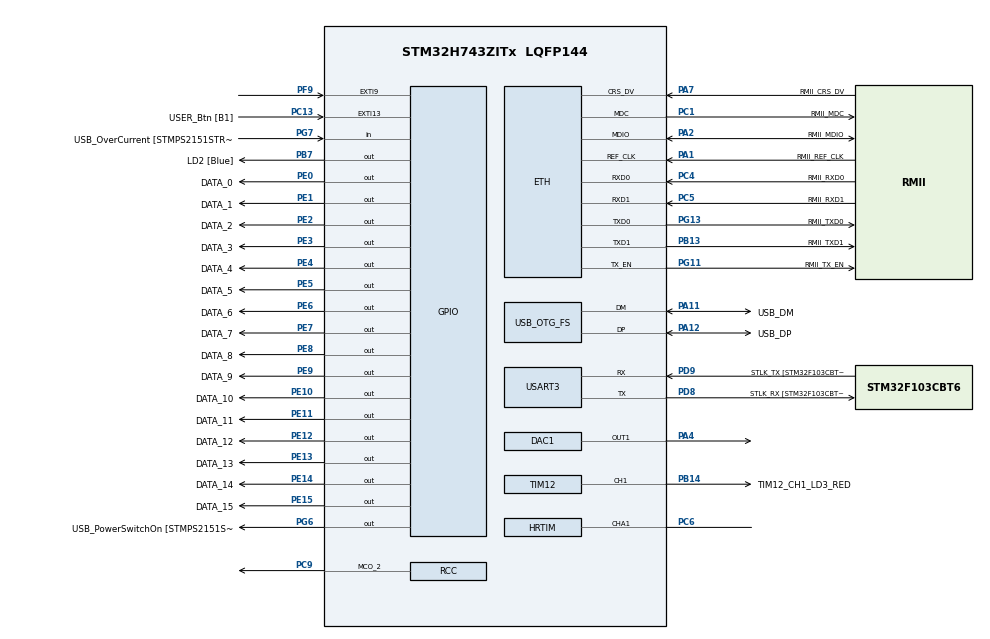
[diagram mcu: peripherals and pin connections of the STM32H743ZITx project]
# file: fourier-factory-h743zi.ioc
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Dma.HRTIM1_A.0.Direction=DMA_MEMORY_TO_PERIPH
Dma.HRTIM1_A.0.EventEnable=DISABLE
Dma.HRTIM1_A.0.FIFOMode=DMA_FIFOMODE_ENABLE
Dma.HRTIM1_A.0.FIFOThreshold=DMA_FIFO_THRESHOLD_FULL
Dma.HRTIM1_A.0.Instance=DMA1_Stream1
Dma.HRTIM1_A.0.MemBurst=DMA_MBURST_INC8
Dma.HRTIM1_A.0.MemDataAlignment=DMA_MDATAALIGN_HALFWORD
Dma.HRTIM1_A.0.MemInc=DMA_MINC_ENABLE
Dma.HRTIM1_A.0.Mode=DMA_NORMAL
Dma.HRTIM1_A.0.PeriphBurst=DMA_PBURST_INC8
Dma.HRTIM1_A.0.PeriphDataAlignment=DMA_PDATAALIGN_HALFWORD
Dma.HRTIM1_A.0.PeriphInc=DMA_PINC_DISABLE
Dma.HRTIM1_A.0.Polarity=HAL_DMAMUX_REQ_GEN_RISING
Dma.HRTIM1_A.0.Priority=DMA_PRIORITY_VERY_HIGH
Dma.HRTIM1_A.0.RequestNumber=1
Dma.HRTIM1_A.0.SignalID=NONE
Dma.HRTIM1_A.0.SyncEnable=DISABLE
Dma.HRTIM1_A.0.SyncPolarity=HAL_DMAMUX_SYNC_NO_EVENT
Dma.HRTIM1_A.0.SyncRequestNumber=1
Dma.HRTIM1_A.0.SyncSignalID=NONE
Dma.Request0=HRTIM1_A
ETH.MediaInterface=HAL_ETH_RMII_MODE
HRTIM.BurstDMAconfig-Output_TA1=__NULL
HRTIM.CompareUnit1-Output_TA1=HRTIM_COMPAREUNIT_1
HRTIM.CompareUnit2-Output_TA1=HRTIM_COMPAREUNIT_2
HRTIM.CompareValue1-Output_TA1=8
HRTIM.CompareValue2-Output_TA1=17
HRTIM.Configuration_TA=Waveform
HRTIM.DMADstAddress-Output_TA1=(uint32_t)&(GPIOE->ODR)
HRTIM.DMARequests1-Output_TA1=HRTIM_TIM_DMA_SET1
HRTIM.DMARequests2-Output_TA1=HRTIM_TIM_DMA_RST1
HRTIM.DMASize-Output_TA1=1024
HRTIM.DMASrcAddress-Output_TA1=(uint32_t)dac_buffer
HRTIM.NumberDMARequests_TA=1
HRTIM.NumberRegisters_BURSTDMA-Output_TA1=4
HRTIM.NumberResetSource1-Output_TA1=1
HRTIM.NumberSetSource1-Output_TA1=1
HRTIM.Periode_TA=18
HRTIM.ResetOutput1_Source1-Output_TA1=HRTIM_OUTPUTRESET_TIMCMP2
HRTIM.SetOutput1_Source1-Output_TA1=HRTIM_OUTPUTSET_TIMCMP1
Mcu.Family=STM32H7
Mcu.Name=STM32H743ZITx
Mcu.Package=LQFP144
NVIC.DMA1_Stream1_IRQn=true\:0\:0\:false\:false\:true\:false\:true
NVIC.PriorityGroup=NVIC_PRIORITYGROUP_4
NVIC.TIM6_DAC_IRQn=true\:0\:0\:false\:false\:true\:false\:true
NVIC.TimeBase=TIM6_DAC_IRQn
NVIC.TimeBaseIP=TIM6
PA1.GPIO_Label=RMII_REF_CLK
PA1.Mode=RMII
PA1.Signal=ETH_REF_CLK
PA10.GPIO_Label=USB_ID
PA10.Signal=USB_OTG_FS_ID
PA11.GPIO_Label=USB_DM
PA11.Mode=Device_Only
PA11.Signal=USB_OTG_FS_DM
PA12.GPIO_Label=USB_DP
PA12.Mode=Device_Only
PA12.Signal=USB_OTG_FS_DP
PA13\ (JTMS/SWDIO).GPIO_Label=TMS
PA13\ (JTMS/SWDIO).Mode=Serial_Wire
PA13\ (JTMS/SWDIO).Signal=SYS_JTMS-SWDIO
PA14\ (JTCK/SWCLK).GPIO_Label=TCK
PA14\ (JTCK/SWCLK).Mode=Serial_Wire
PA14\ (JTCK/SWCLK).Signal=SYS_JTCK-SWCLK
PA2.GPIO_Label=RMII_MDIO
PA2.Mode=RMII
PA2.Signal=ETH_MDIO
PA4.Signal=COMP_DAC11_group
PA7.GPIO_Label=RMII_CRS_DV
PA7.Mode=RMII
PA7.Signal=ETH_CRS_DV
PA8.GPIO_Label=USB_SOF [TP1]
PA8.Signal=USB_OTG_FS_SOF
PA9.GPIO_Label=USB_VBUS
PA9.Signal=USB_OTG_FS_VBUS
PB13.GPIO_Label=RMII_TXD1
PB13.Mode=RMII
PB13.Signal=ETH_TXD1
PB14.GPIO_Label=TIM12_CH1_LD3_RED
PB14.Signal=S_TIM12_CH1
PB3\ (JTDO/TRACESWO).GPIO_Label=SWO
PB3\ (JTDO/TRACESWO).Signal=SYS_JTDO-SWO
PB7.GPIO_Label=LD2 [Blue]
PB7.Signal=GPIO_Output
PC1.GPIO_Label=RMII_MDC
PC1.Mode=RMII
PC1.Signal=ETH_MDC
PC13.GPIO_Label=USER_Btn [B1]
PC13.Signal=GPXTI13
PC14-OSC32_IN\ (OSC32_IN).Mode=LSE-External-Oscillator
PC14-OSC32_IN\ (OSC32_IN).Signal=RCC_OSC32_IN
PC15-OSC32_OUT\ (OSC32_OUT).Mode=LSE-External-Oscillator
PC15-OSC32_OUT\ (OSC32_OUT).Signal=RCC_OSC32_OUT
PC4.GPIO_Label=RMII_RXD0
PC4.Mode=RMII
PC4.Signal=ETH_RXD0
PC5.GPIO_Label=RMII_RXD1
PC5.Mode=RMII
PC5.Signal=ETH_RXD1
PC6.Mode=Output_TA1
PC6.Signal=HRTIM_CHA1
PC9.Mode=Clock-out-2
PC9.Signal=RCC_MCO_2
PD8.GPIO_Label=STLK_RX [STM32F103CBT6_PA3]
PD8.Mode=Asynchronous
PD8.Signal=USART3_TX
PD9.GPIO_Label=STLK_TX [STM32F103CBT6_PA2]
PD9.Mode=Asynchronous
PD9.Signal=USART3_RX
PE0.GPIO_Label=DATA_0
PE0.GPIO_Speed=GPIO_SPEED_FREQ_VERY_HIGH
PE0.Signal=GPIO_Output
PE1.GPIO_Label=DATA_1
PE1.GPIO_Speed=GPIO_SPEED_FREQ_VERY_HIGH
PE1.Signal=GPIO_Output
PE10.GPIO_Label=DATA_10
PE10.GPIO_Speed=GPIO_SPEED_FREQ_VERY_HIGH
PE10.Signal=GPIO_Output
PE11.GPIO_Label=DATA_11
PE11.GPIO_Speed=GPIO_SPEED_FREQ_VERY_HIGH
PE11.Signal=GPIO_Output
PE12.GPIO_Label=DATA_12
PE12.GPIO_Speed=GPIO_SPEED_FREQ_VERY_HIGH
PE12.Signal=GPIO_Output
PE13.GPIO_Label=DATA_13
PE13.GPIO_Speed=GPIO_SPEED_FREQ_VERY_HIGH
PE13.Signal=GPIO_Output
PE14.GPIO_Label=DATA_14
PE14.GPIO_Speed=GPIO_SPEED_FREQ_VERY_HIGH
PE14.Signal=GPIO_Output
PE15.GPIO_Label=DATA_15
PE15.GPIO_Speed=GPIO_SPEED_FREQ_VERY_HIGH
PE15.Signal=GPIO_Output
PE2.GPIO_Label=DATA_2
PE2.GPIO_Speed=GPIO_SPEED_FREQ_VERY_HIGH
PE2.Signal=GPIO_Output
PE3.GPIO_Label=DATA_3
PE3.GPIO_Speed=GPIO_SPEED_FREQ_VERY_HIGH
PE3.Signal=GPIO_Output
PE4.GPIO_Label=DATA_4
PE4.GPIO_Speed=GPIO_SPEED_FREQ_VERY_HIGH
PE4.Signal=GPIO_Output
PE5.GPIO_Label=DATA_5
PE5.GPIO_Speed=GPIO_SPEED_FREQ_VERY_HIGH
PE5.Signal=GPIO_Output
PE6.GPIO_Label=DATA_6
PE6.GPIO_Speed=GPIO_SPEED_FREQ_VERY_HIGH
PE6.Signal=GPIO_Output
PE7.GPIO_Label=DATA_7
PE7.GPIO_Speed=GPIO_SPEED_FREQ_VERY_HIGH
PE7.Signal=GPIO_Output
PE8.GPIO_Label=DATA_8
PE8.GPIO_Speed=GPIO_SPEED_FREQ_VERY_HIGH
PE8.Signal=GPIO_Output
PE9.GPIO_Label=DATA_9
PE9.GPIO_Speed=GPIO_SPEED_FREQ_VERY_HIGH
PE9.Signal=GPIO_Output
PF9.Signal=GPXTI9
PG11.GPIO_Label=RMII_TX_EN
PG11.Mode=RMII
PG11.Signal=ETH_TX_EN
PG13.GPIO_Label=RMII_TXD0
PG13.Mode=RMII
PG13.Signal=ETH_TXD0
PG6.GPIO_Label=USB_PowerSwitchOn [STMPS2151STR_EN]
PG6.Signal=GPIO_Output
PG7.GPIO_Label=USB_OverCurrent [STMPS2151STR_FAULT]
PG7.Signal=GPIO_Input
PH0-OSC_IN\ (PH0).GPIO_Label=MCO
PH0-OSC_IN\ (PH0).Mode=HSE-External-Oscillator
PH0-OSC_IN\ (PH0).Signal=RCC_OSC_IN
PH1-OSC_OUT\ (PH1).Mode=HSE-External-Oscillator
PH1-OSC_OUT\ (PH1).Signal=RCC_OSC_OUT
ProjectManager.HeapSize=0x200
ProjectManager.StackSize=0x400
ProjectManager.TargetToolchain=SW4STM32
RCC.48MHZClocksFreq_Value=24000000
RCC.ADCFreq_Value=16125000
RCC.AHBFreq_Value=216000000
RCC.APB1CLKDivider=RCC_HCLK_DIV4
RCC.APB1Freq_Value=100000000
RCC.APB1TimFreq_Value=108000000
RCC.APB2CLKDivider=RCC_HCLK_DIV2
RCC.APB2Freq_Value=100000000
RCC.APB2TimFreq_Value=216000000
RCC.APB3Freq_Value=100000000
RCC.APB4Freq_Value=100000000
RCC.CortexFreq_Value=400000000
RCC.D1PPRE=RCC_APB3_DIV2
RCC.D2PPRE1=RCC_APB1_DIV2
RCC.D2PPRE2=RCC_APB2_DIV2
RCC.D3PPRE=RCC_APB4_DIV2
RCC.DIVM1=1
RCC.DIVN1=100
RCC.DIVQ1=4
RCC.EnbaleCSS=true
RCC.HCLKFreq_Value=200000000
RCC.HPRE=RCC_HCLK_DIV2
RCC.HRTIMCLockSelection=RCC_HRTIM1CLK_CPUCLK
RCC.HSE_VALUE=8000000
RCC.HSI_VALUE=64000000
RCC.PLLM=25
RCC.PLLMUL=RCC_PLL_MUL9
RCC.PLLN=432
RCC.PLLQ=9
RCC.PLLSourceVirtual=RCC_PLLSOURCE_HSE
RCC.PRESCALERUSB=RCC_USBCLKSOURCE_PLL_DIV1_5
RCC.PWR_Regulator_Voltage_Scale=PWR_REGULATOR_VOLTAGE_SCALE1
RCC.RCC_MCODiv2=RCC_MCODIV_4
RCC.SYSCLKFreq_VALUE=400000000
RCC.SYSCLKSource=RCC_SYSCLKSOURCE_PLLCLK
RCC.SYSCLKSourceVirtual=RCC_SYSCLKSOURCE_PLLCLK
RCC.USBCLockSelection=RCC_USBCLKSOURCE_HSI48
RCC.USBFreq_Value=48000000
RCC.VCOOutputFreq_Value=432000000
SH.COMP_DAC11_group.0=DAC1_OUT1,DAC_OUT1_ExtAndInt
SH.S_TIM12_CH1.0=TIM12_CH1,PWM Generation1 CH1
TIM12.Channel-PWM\ Generation1\ CH1=TIM_CHANNEL_1
TIM12.ClockDivision=TIM_CLOCKDIVISION_DIV1
TIM12.Period=10000
USART3.VirtualMode-Asynchronous=VM_ASYNC
USB_OTG_FS.VirtualMode=Device_Only
VP_RNG_VS_RNG.Mode=RNG_Activate
VP_SYS_VS_tim6.Mode=TIM6
VP_TIM12_VS_ClockSourceINT.Mode=Internal
board=NUCLEO-H743ZI

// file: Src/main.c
/* USER CODE BEGIN Header */
/**
  ******************************************************************************
  * @file           : main.c
  * @brief          : Main program body
  ******************************************************************************
  * @attention
  *
  * <h2><center>&copy; Copyright (c) 2019 STMicroelectronics.
  * All rights reserved.</center></h2>
  *
  * This software component is licensed by ST under BSD 3-Clause license,
  * the "License"; You may not use this file except in compliance with the
  * License. You may obtain a copy of the License at:
  *                        opensource.org/licenses/BSD-3-Clause
  *
  ******************************************************************************
  */
#define _MAIN_C
/* USER CODE END Header */

#include "main.h"
#include "dac.h"
#include "dma.h"
#include "eth.h"
#include "hrtim.h"
#include "rng.h"
#include "tim.h"
#include "usart.h"
#include "usb_otg.h"
#include "gpio.h"

void SystemClock_Config(void);

int main(void)
{
  /* USER CODE BEGIN 1 */
  uint32_t i;
  /* USER CODE END 1 */

  /* MCU Configuration--------------------------------------------------------*/

  /* Reset of all peripherals, Initializes the Flash interface and the Systick. */
  HAL_Init();

  /* Configure the system clock */
  SystemClock_Config();

  /* Initialize all configured peripherals */
  MX_GPIO_Init();
  MX_DMA_Init();
  MX_ETH_Init();
  MX_USART3_UART_Init();
  MX_DAC1_Init();
  MX_RNG_Init();
  MX_TIM12_Init();
  MX_USB_OTG_FS_PCD_Init();
  MX_HRTIM_Init();

  /* Infinite loop */
  /* USER CODE BEGIN WHILE */

  // Need to enable SRAM1 before using that memory
  RCC->AHB2ENR |= RCC_AHB2ENR_D2SRAM1EN;
  //RCC->AHB2ENR |= RCC_AHB2ENR_D2SRAM2EN;
  //RCC->AHB2ENR |= RCC_AHB2ENR_D2SRAM3EN;

  for (i=0; i < DAC_BUFFER_SIZE; i++) {
	  dac_buffer[i] = i;
  }

  // Code for starting TA1 (OC) & TA2 (PWM) outputs in "simple" mode
  //HAL_HRTIM_SimpleOCStart(&hhrtim, HRTIM_TIMERINDEX_TIMER_A, HRTIM_OUTPUT_TA1);
  //HAL_HRTIM_SimplePWMStart(&hhrtim, HRTIM_TIMERINDEX_TIMER_A, HRTIM_OUTPUT_TA2);

  __disable_irq();
  // Code for starting TA1 outputs in "advanced" mode w/ DMA
  HAL_HRTIM_WaveformOutputStart(&hhrtim, HRTIM_OUTPUT_TA1);
  HAL_HRTIM_WaveformCounterStart_DMA(&hhrtim, HRTIM_TIMERID_TIMER_A);
  DMA1_Stream1->CR &= ~DMA_IT_HT; // disable half-transfer complete interrupts
  __enable_irq();

  while (1)
  {
    /* USER CODE END WHILE */

    /* USER CODE BEGIN 3 */
	  __NOP();	// Just so we have something to set a breakpoint on / not optimize out
  }
  /* USER CODE END 3 */
}

void SystemClock_Config(void)
{
  RCC_OscInitTypeDef RCC_OscInitStruct = {0};
  RCC_ClkInitTypeDef RCC_ClkInitStruct = {0};
  RCC_PeriphCLKInitTypeDef PeriphClkInitStruct = {0};

  /** Supply configuration update enable
  */
  MODIFY_REG(PWR->CR3, PWR_CR3_SCUEN, 0);
  /** Configure the main internal regulator output voltage
  */
  __HAL_PWR_VOLTAGESCALING_CONFIG(PWR_REGULATOR_VOLTAGE_SCALE1);

  while ((PWR->D3CR & (PWR_D3CR_VOSRDY)) != PWR_D3CR_VOSRDY)
  {

  }
  /** Initializes the CPU, AHB and APB busses clocks
  */
  RCC_OscInitStruct.OscillatorType = RCC_OSCILLATORTYPE_HSI48|RCC_OSCILLATORTYPE_HSE;
  RCC_OscInitStruct.HSEState = RCC_HSE_ON;
  RCC_OscInitStruct.HSI48State = RCC_HSI48_ON;
  RCC_OscInitStruct.PLL.PLLState = RCC_PLL_ON;
  RCC_OscInitStruct.PLL.PLLSource = RCC_PLLSOURCE_HSE;
  RCC_OscInitStruct.PLL.PLLM = 1;
  RCC_OscInitStruct.PLL.PLLN = 100;
  RCC_OscInitStruct.PLL.PLLP = 2;
  RCC_OscInitStruct.PLL.PLLQ = 4;
  RCC_OscInitStruct.PLL.PLLR = 2;
  RCC_OscInitStruct.PLL.PLLRGE = RCC_PLL1VCIRANGE_3;
  RCC_OscInitStruct.PLL.PLLVCOSEL = RCC_PLL1VCOWIDE;
  RCC_OscInitStruct.PLL.PLLFRACN = 0;
  if (HAL_RCC_OscConfig(&RCC_OscInitStruct) != HAL_OK)
  {
    Error_Handler();
  }
  /** Initializes the CPU, AHB and APB busses clocks
  */
  RCC_ClkInitStruct.ClockType = RCC_CLOCKTYPE_HCLK|RCC_CLOCKTYPE_SYSCLK
                              |RCC_CLOCKTYPE_PCLK1|RCC_CLOCKTYPE_PCLK2
                              |RCC_CLOCKTYPE_D3PCLK1|RCC_CLOCKTYPE_D1PCLK1;
  RCC_ClkInitStruct.SYSCLKSource = RCC_SYSCLKSOURCE_PLLCLK;
  RCC_ClkInitStruct.SYSCLKDivider = RCC_SYSCLK_DIV1;
  RCC_ClkInitStruct.AHBCLKDivider = RCC_HCLK_DIV2;
  RCC_ClkInitStruct.APB3CLKDivider = RCC_APB3_DIV2;
  RCC_ClkInitStruct.APB1CLKDivider = RCC_APB1_DIV2;
  RCC_ClkInitStruct.APB2CLKDivider = RCC_APB2_DIV2;
  RCC_ClkInitStruct.APB4CLKDivider = RCC_APB4_DIV2;

  if (HAL_RCC_ClockConfig(&RCC_ClkInitStruct, FLASH_LATENCY_2) != HAL_OK)
  {
    Error_Handler();
  }
  PeriphClkInitStruct.PeriphClockSelection = RCC_PERIPHCLK_HRTIM1|RCC_PERIPHCLK_USART3
                              |RCC_PERIPHCLK_RNG|RCC_PERIPHCLK_USB;
  PeriphClkInitStruct.Usart234578ClockSelection = RCC_USART234578CLKSOURCE_D2PCLK1;
  PeriphClkInitStruct.RngClockSelection = RCC_RNGCLKSOURCE_HSI48;
  PeriphClkInitStruct.UsbClockSelection = RCC_USBCLKSOURCE_HSI48;
  PeriphClkInitStruct.Hrtim1ClockSelection = RCC_HRTIM1CLK_CPUCLK;
  if (HAL_RCCEx_PeriphCLKConfig(&PeriphClkInitStruct) != HAL_OK)
  {
    Error_Handler();
  }
  HAL_RCC_MCOConfig(RCC_MCO2, RCC_MCO2SOURCE_SYSCLK, RCC_MCODIV_4);
  /** Enables the Clock Security System
  */
  HAL_RCC_EnableCSS();
}

void HAL_TIM_PeriodElapsedCallback(TIM_HandleTypeDef *htim)
{
  if (htim->Instance == TIM6) {
    HAL_IncTick();
  }
}

void Error_Handler(void)
{
}

/************************ (C) COPYRIGHT STMicroelectronics *****END OF FILE****/
